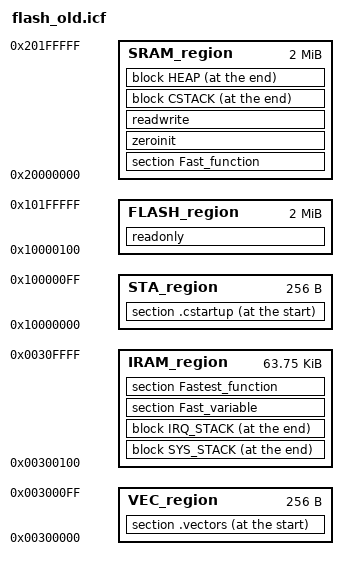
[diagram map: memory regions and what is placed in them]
/*###ICF### Section handled by ICF editor, don't touch! ****/
/*-Editor annotation file-*/
/* IcfEditorFile="$TOOLKIT_DIR$\config\ide\IcfEditor\a_v1_0.xml" */
/*-Memory Regions-*/
define symbol __ICFEDIT_region_SRAM_start__ = 0x20000000;
define symbol __ICFEDIT_region_SRAM_end__   = 0x201FFFFF;
define symbol __ICFEDIT_region_FLASH_start__ = 0x10000000;
define symbol __ICFEDIT_region_FLASH_end__   = 0x101FFFFF;
define symbol __ICFEDIT_region_RAM_start__   = 0x200000;
define symbol __ICFEDIT_region_RAM_end__     = 0x203FFF;
define symbol __ICFEDIT_region_IRAM_start__   = 0x300000;
define symbol __ICFEDIT_region_IRAM_end__     = 0x30FFFF;

/*-Sizes-*/
define symbol __ICFEDIT_size_region_FLASH__   = 0x200000;
define symbol __ICFEDIT_size_startup__  = 0x100;
define symbol __ICFEDIT_size_vectors__  = 0x100;
define symbol __ICFEDIT_size_cstack__   = 0x2000;
define symbol __ICFEDIT_size_sysstack__ = 0x60;
define symbol __ICFEDIT_size_irqstack__ = 0x60;
define symbol __ICFEDIT_size_heap__     = 0x0;

/*-Exports-*/
export symbol __ICFEDIT_region_SRAM_start__;
export symbol __ICFEDIT_region_SRAM_end__;
export symbol __ICFEDIT_region_IRAM_start__;
export symbol __ICFEDIT_region_IRAM_end__;
export symbol __ICFEDIT_region_FLASH_start__;
export symbol  __ICFEDIT_size_region_FLASH__;
export symbol __ICFEDIT_region_RAM_start__;
export symbol __ICFEDIT_region_RAM_end__;
export symbol __ICFEDIT_size_startup__;
export symbol __ICFEDIT_size_vectors__;
export symbol __ICFEDIT_size_cstack__;
export symbol __ICFEDIT_size_sysstack__;
export symbol __ICFEDIT_size_irqstack__;
export symbol __ICFEDIT_size_heap__;
//.export symbol __ICFEDIT_region_RAM1_start__;
//.export symbol __ICFEDIT_region_RAM1_end__;
/**** End of ICF editor section. ###ICF###*/

define memory mem with size = 4G;
define region STA_region =   mem:[from __ICFEDIT_region_FLASH_start__ size __ICFEDIT_size_startup__];
define region FLASH_region = mem:[from (__ICFEDIT_region_FLASH_start__+__ICFEDIT_size_startup__) size  (__ICFEDIT_size_region_FLASH__ - __ICFEDIT_size_startup__) ];
//.define region SDRAM_region = mem:[from __ICFEDIT_region_SDRAM_start__ to __ICFEDIT_region_SDRAM_end__];
define region SRAM_region = mem:[from __ICFEDIT_region_SRAM_start__ to __ICFEDIT_region_SRAM_end__];
//.define region VEC_region =   mem:[from __ICFEDIT_region_RAM_start__ size __ICFEDIT_size_vectors__];
define region VEC_region =   mem:[from __ICFEDIT_region_IRAM_start__ size __ICFEDIT_size_vectors__];
define region IRAM_region =   mem:[from __ICFEDIT_region_IRAM_start__+__ICFEDIT_size_vectors__ to __ICFEDIT_region_IRAM_end__];
//.define region RAM_region =   mem:[from __ICFEDIT_region_RAM_start__+__ICFEDIT_size_vectors__ to __ICFEDIT_region_RAM_end__];
//.define region RAM1_region =  mem:[from __ICFEDIT_region_RAM1_start__ to __ICFEDIT_region_RAM1_end__];

define block CSTACK    with alignment = 8, size = __ICFEDIT_size_cstack__   { };
define block SYS_STACK with alignment = 8, size = __ICFEDIT_size_sysstack__ { };
define block IRQ_STACK with alignment = 8, size = __ICFEDIT_size_irqstack__ { };
define block HEAP      with alignment = 8, size = __ICFEDIT_size_heap__     { };
/*
//define block CHECKSUM { ro section .checksum };

keep { section MYOVERLAY1,section MYOVERLAY2 };

//define overlay MYOVERLAY { section MYOVERLAY1 };
//define overlay MYOVERLAY { section MYOVERLAY2 };

initialize manually { section MYOVERLAY1, section MYOVERLAY2 };
*/
initialize by copy { section .vectors };
initialize by copy { readwrite };
initialize by copy with packing = zeros { section Fastest_function };
initialize by copy with packing = zeros { section Fast_function };
do not initialize  { section .noinit };
/*overlay MYOVERLAY,*/
/*place at address mem:0x0300500 {overlay MYOVERLAY};*/
place at start of STA_region { section .cstartup };
place at start of VEC_region { section .vectors };
place at end of IRAM_region {block SYS_STACK, block IRQ_STACK};
/*
//.place in RAM1_region {section Fast_variable, section Fastest_function};
*/
place in IRAM_region {section Fast_variable, section Fastest_function};

/*place in FLASH_region {readonly, section MYOVERLAY1_init, section MYOVERLAY2_init,
						block CHECKSUM};
						*/
place in FLASH_region {readonly}; /*, block CHECKSUM};*/
/*place at end of FLASH_region {ro section .checksum};*/
/*
//place in SDRAM_region {section Fast_function, zeroinit, readwrite};
//place at end of SDRAM_region {block CSTACK, block HEAP };
*/
place in SRAM_region {section Fast_function, zeroinit, readwrite};
place at end of SRAM_region {block CSTACK, block HEAP };

